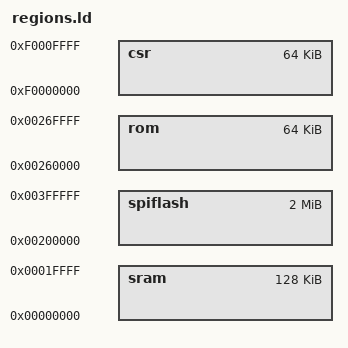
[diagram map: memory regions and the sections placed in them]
MEMORY {
	sram : ORIGIN = 0x00000000, LENGTH = 0x00020000
	spiflash : ORIGIN = 0x00200000, LENGTH = 0x00200000
	rom : ORIGIN = 0x00260000, LENGTH = 0x00010000
	csr : ORIGIN = 0xf0000000, LENGTH = 0x00010000
}
